# MK11DA5 register map
Vendor: Freescale Semiconductor, Inc.; Series: Kinetis_K; File version: 1.6
CPU: CM4 r0p1, little endian, no MPU, no FPU, VTOR, 4 interrupt priority bits
Registers are 8-bit, read-write, reset 0x0 unless marked. A register's access mark holds for its fields unless they carry their own. Offsets are from the block's base; [hi:lo] are bit positions; {n}, {i} and the like mark numbered series; 'fields as' and 'values as' point back to an identical list.

## FMC — Flash Memory Controller
Base 0x4001F000; register names take the prefix FMC_
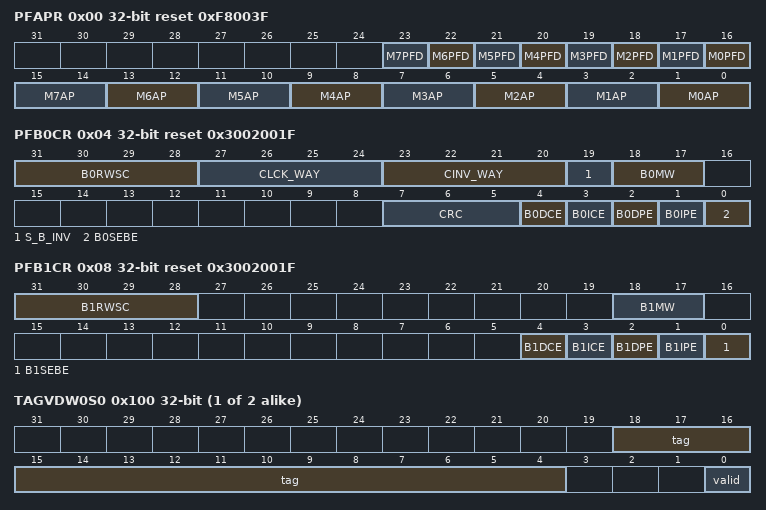
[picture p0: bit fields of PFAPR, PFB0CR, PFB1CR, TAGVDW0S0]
0x00 PFAPR 32-bit reset 0xF8003F — Flash Access Protection Register
  [n+16] M{n}PFD (n=0..7) — Master {n} Prefetch Disable
    0=Prefetching for this master is enabled; 1=Prefetching for this master is disabled
  [2n+1:2n] M{n}AP (n=0..7) — Master {n} Access Protection
    0=No access may be performed by this master; 1=Only read accesses may be performed by this master; 2=Only write accesses may be performed by this master; 3=Both read and write accesses may be performed by this master
0x04 PFB0CR 32-bit reset 0x3002001F — Flash Bank 0 Control Register
  [31:28] B0RWSC ro — Bank 0 Read Wait State Control
  [27:24] CLCK_WAY — Cache Lock Way x
    0=Cache way is unlocked and may be displaced; 1=Cache way is locked and its contents are not displaced
  [23:20] CINV_WAY wo — Cache Invalidate Way x
    0=No cache way invalidation for the corresponding cache; 1=Invalidate cache way for the corresponding cache: clear the tag, data, and vld bits of ways selected
  [19] S_B_INV wo — Invalidate Prefetch Speculation Buffer
    0=Speculation buffer and single entry buffer are not affected; 1=Invalidate (clear) speculation buffer and single entry buffer
  [18:17] B0MW ro — Bank 0 Memory Width
    0=32 bits; 1=64 bits
  [7:5] CRC — Cache Replacement Control
    0=LRU replacement algorithm per set across all four ways; 2=Independent LRU with ways [0-1] for ifetches, [2-3] for data; 3=Independent LRU with ways [0-2] for ifetches, [3] for data
  [4] B0DCE — Bank 0 Data Cache Enable
    0=Do not cache data references; 1=Cache data references
  [3] B0ICE — Bank 0 Instruction Cache Enable
    0=Do not cache instruction fetches; 1=Cache instruction fetches
  [2] B0DPE — Bank 0 Data Prefetch Enable
    0=Do not prefetch in response to data references; 1=Enable prefetches in response to data references
  [1] B0IPE — Bank 0 Instruction Prefetch Enable
    0=Do not prefetch in response to instruction fetches; 1=Enable prefetches in response to instruction fetches
  [0] B0SEBE — Bank 0 Single Entry Buffer Enable
    0=Single entry buffer is disabled; 1=Single entry buffer is enabled
0x08 PFB1CR 32-bit reset 0x3002001F — Flash Bank 1 Control Register
  [31:28] B1RWSC ro — Bank 1 Read Wait State Control
  [18:17] B1MW ro — Bank 1 Memory Width
    0=32 bits; 1=64 bits
  [4] B1DCE — Bank 1 Data Cache Enable
    0=Do not cache data references; 1=Cache data references
  [3] B1ICE — Bank 1 Instruction Cache Enable
    values as PFB0CR.B0ICE
  [2] B1DPE — Bank 1 Data Prefetch Enable
    values as PFB0CR.B0DPE
  [1] B1IPE — Bank 1 Instruction Prefetch Enable
    values as PFB0CR.B0IPE
  [0] B1SEBE — Bank 1 Single Entry Buffer Enable
    values as PFB0CR.B0SEBE
{0x100+4i} TAGVDW0S{i} (i=0..1) 32-bit — Cache Tag Storage
  [18:4] tag — 15-bit tag for cache entry
  [0] valid — 1-bit valid for cache entry
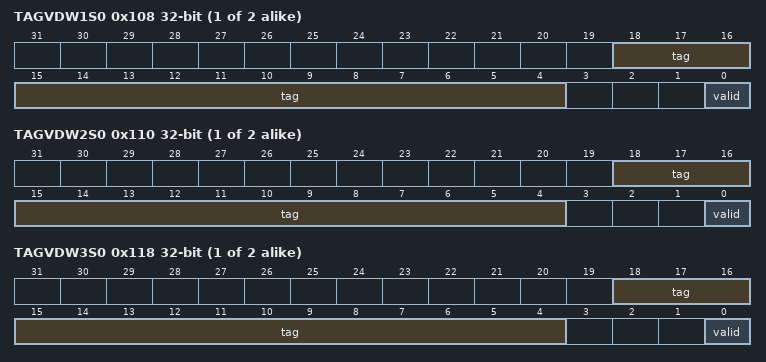
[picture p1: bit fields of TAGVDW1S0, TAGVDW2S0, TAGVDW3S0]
{0x108+4i} TAGVDW1S{i} (i=0..1) 32-bit — Cache Tag Storage
  fields as TAGVDW0S0
{0x110+4i} TAGVDW2S{i} (i=0..1) 32-bit — Cache Tag Storage
  fields as TAGVDW0S0
{0x118+4i} TAGVDW3S{i} (i=0..1) 32-bit — Cache Tag Storage
  fields as TAGVDW0S0
{0x200+8i} DATAW0S{i}U (i=0..1) 32-bit — Cache Data Storage (upper word)
  [31:0] data — Bits [63:32] of data entry
{0x204+8i} DATAW0S{i}L (i=0..1) 32-bit — Cache Data Storage (lower word)
  [31:0] data — Bits [31:0] of data entry
{0x210+8i} DATAW1S{i}U (i=0..1) 32-bit — Cache Data Storage (upper word)
  [31:0] data — Bits [63:32] of data entry
{0x214+8i} DATAW1S{i}L (i=0..1) 32-bit — Cache Data Storage (lower word)
  [31:0] data — Bits [31:0] of data entry
{0x220+8i} DATAW2S{i}U (i=0..1) 32-bit — Cache Data Storage (upper word)
  [31:0] data — Bits [63:32] of data entry
{0x224+8i} DATAW2S{i}L (i=0..1) 32-bit — Cache Data Storage (lower word)
  [31:0] data — Bits [31:0] of data entry
{0x230+8i} DATAW3S{i}U (i=0..1) 32-bit — Cache Data Storage (upper word)
  [31:0] data — Bits [63:32] of data entry
{0x234+8i} DATAW3S{i}L (i=0..1) 32-bit — Cache Data Storage (lower word)
  [31:0] data — Bits [31:0] of data entry

## Notices in the file
Redistribution and use in source and binary forms, with or without modification,
are permitted provided that the following conditions are met:
o Redistributions of source code must retain the above copyright notice, this list
of conditions and the following disclaimer.
o Redistributions in binary form must reproduce the above copyright notice, this
list of conditions and the following disclaimer in the documentation and/or
other materials provided with the distribution.
o Neither the name of Freescale Semiconductor, Inc. nor the names of its
contributors may be used to endorse or promote products derived from this
software without specific prior written permission.
THIS SOFTWARE IS PROVIDED BY THE COPYRIGHT HOLDERS AND CONTRIBUTORS "AS IS" AND
ANY EXPRESS OR IMPLIED WARRANTIES, INCLUDING, BUT NOT LIMITED TO, THE IMPLIED
WARRANTIES OF MERCHANTABILITY AND FITNESS FOR A PARTICULAR PURPOSE ARE
DISCLAIMED. IN NO EVENT SHALL THE COPYRIGHT HOLDER OR CONTRIBUTORS BE LIABLE FOR
ANY DIRECT, INDIRECT, INCIDENTAL, SPECIAL, EXEMPLARY, OR CONSEQUENTIAL DAMAGES
(INCLUDING, BUT NOT LIMITED TO, PROCUREMENT OF SUBSTITUTE GOODS OR SERVICES;
LOSS OF USE, DATA, OR PROFITS; OR BUSINESS INTERRUPTION) HOWEVER CAUSED AND ON
ANY THEORY OF LIABILITY, WHETHER IN CONTRACT, STRICT LIABILITY, OR TORT
(INCLUDING NEGLIGENCE OR OTHERWISE) ARISING IN ANY WAY OUT OF THE USE OF THIS
SOFTWARE, EVEN IF ADVISED OF THE POSSIBILITY OF SUCH DAMAGE.
